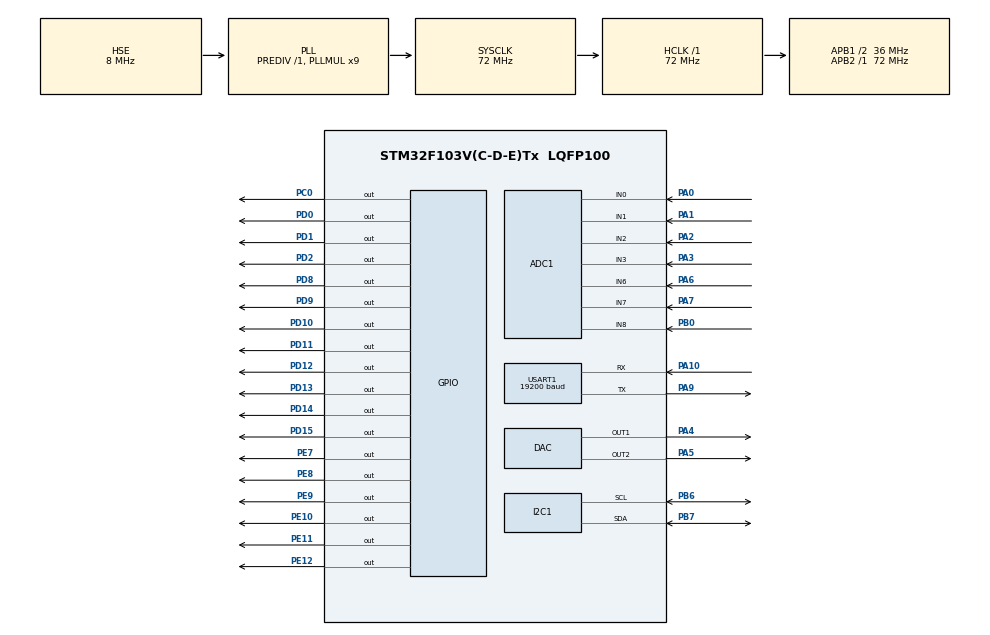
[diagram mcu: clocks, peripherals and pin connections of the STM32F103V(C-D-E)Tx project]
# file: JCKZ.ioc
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ADC1.Channel-10\#ChannelRegularConversion=ADC_CHANNEL_0
ADC1.ContinuousConvMode=DISABLE
ADC1.DataAlign=ADC_DATAALIGN_RIGHT
ADC1.DiscontinuousConvMode=DISABLE
ADC1.EnableAnalogWatchDog=false
ADC1.EnableRegularConversion=ENABLE
ADC1.ExternalTrigConv=ADC_SOFTWARE_START
ADC1.InjNumberOfConversion=0
ADC1.NbrOfConversion=1
ADC1.NbrOfConversionFlag=1
ADC1.Rank-10\#ChannelRegularConversion=1
ADC1.SamplingTime-10\#ChannelRegularConversion=ADC_SAMPLETIME_1CYCLE_5
ADC1.ScanConvMode=ADC_SCAN_DISABLE
ADC1.master=1
FREERTOS.Tasks01=TaskModbusRec,0,128,FuncModbusRec,Default,NULL,Dynamic,NULL,NULL;TaskDataProc,0,128,FuncDataProc,Default,NULL,Dynamic,NULL,NULL;TaskModbusSend,0,128,FuncModbusSend,Default,NULL,Dynamic,NULL,NULL
Mcu.Family=STM32F1
Mcu.Name=STM32F103V(C-D-E)Tx
Mcu.Package=LQFP100
NVIC.ADC1_2_IRQn=true\:5\:0\:false\:false\:true\:true\:true
NVIC.PriorityGroup=NVIC_PRIORITYGROUP_4
NVIC.TIM4_IRQn=true\:0\:0\:false\:false\:true\:false\:false
NVIC.TimeBase=TIM4_IRQn
NVIC.TimeBaseIP=TIM4
NVIC.USART1_IRQn=true\:5\:0\:false\:false\:true\:true\:true
OSC_IN.Mode=HSE-External-Oscillator
OSC_IN.Signal=RCC_OSC_IN
OSC_OUT.Mode=HSE-External-Oscillator
OSC_OUT.Signal=RCC_OSC_OUT
PA0-WKUP.Signal=ADCx_IN0
PA1.Signal=ADCx_IN1
PA10.Mode=Asynchronous
PA10.Signal=USART1_RX
PA2.Signal=ADCx_IN2
PA3.Signal=ADCx_IN3
PA4.Signal=COMP_DAC1_group
PA5.Signal=COMP_DAC2_group
PA6.Signal=ADCx_IN6
PA7.Signal=ADCx_IN7
PA9.Mode=Asynchronous
PA9.Signal=USART1_TX
PB0.Signal=ADCx_IN8
PB6.Mode=I2C
PB6.Signal=I2C1_SCL
PB7.Mode=I2C
PB7.Signal=I2C1_SDA
PC0.Signal=GPIO_Output
PD0.Signal=GPIO_Output
PD1.Signal=GPIO_Output
PD10.Signal=GPIO_Output
PD11.Signal=GPIO_Output
PD12.Signal=GPIO_Output
PD13.Signal=GPIO_Output
PD14.Signal=GPIO_Output
PD15.Signal=GPIO_Output
PD2.Signal=GPIO_Output
PD8.Signal=GPIO_Output
PD9.Signal=GPIO_Output
PE10.Signal=GPIO_Output
PE11.Signal=GPIO_Output
PE12.Signal=GPIO_Output
PE7.Signal=GPIO_Output
PE8.Signal=GPIO_Output
PE9.Signal=GPIO_Output
ProjectManager.HeapSize=0x200
ProjectManager.StackSize=0x400
ProjectManager.TargetToolchain=TrueSTUDIO
RCC.ADCPresc=RCC_ADCPCLK2_DIV6
RCC.AHBFreq_Value=72000000
RCC.APB1CLKDivider=RCC_HCLK_DIV2
RCC.APB1Freq_Value=36000000
RCC.APB1TimFreq_Value=72000000
RCC.APB2Freq_Value=72000000
RCC.APB2TimFreq_Value=72000000
RCC.HCLKFreq_Value=72000000
RCC.PLLMUL=RCC_PLL_MUL9
RCC.PLLSourceVirtual=RCC_PLLSOURCE_HSE
RCC.SYSCLKFreq_VALUE=72000000
RCC.SYSCLKSource=RCC_SYSCLKSOURCE_PLLCLK
RCC.USBFreq_Value=72000000
SH.ADCx_IN0.0=ADC1_IN0,IN0
SH.ADCx_IN1.0=ADC1_IN1,IN1
SH.ADCx_IN2.0=ADC1_IN2,IN2
SH.ADCx_IN3.0=ADC1_IN3,IN3
SH.ADCx_IN6.0=ADC1_IN6,IN6
SH.ADCx_IN7.0=ADC1_IN7,IN7
SH.ADCx_IN8.0=ADC1_IN8,IN8
SH.COMP_DAC1_group.0=DAC_OUT1,DAC_OUT1
SH.COMP_DAC2_group.0=DAC_OUT2,DAC_OUT2
USART1.BaudRate=19200
USART1.VirtualMode=VM_ASYNC
VP_FREERTOS_VS_ENABLE.Mode=Enabled
VP_SYS_VS_ND.Mode=No_Debug
VP_SYS_VS_tim4.Mode=TIM4
board=JCKZ

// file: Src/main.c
/**
  ******************************************************************************
  * File Name          : main.c
  * Description        : Main program body
  ******************************************************************************
  * This notice applies to any and all portions of this file
  * that are not between comment pairs USER CODE BEGIN and
  * USER CODE END. Other portions of this file, whether
  * inserted by the user or by software development tools
  * are owned by their respective copyright owners.
  *
  * Copyright (c) 2017 STMicroelectronics International N.V.
  * All rights reserved.
  *
  * Redistribution and use in source and binary forms, with or without
  * modification, are permitted, provided that the following conditions are met:
  *
  * 1. Redistribution of source code must retain the above copyright notice,
  *    this list of conditions and the following disclaimer.
  * 2. Redistributions in binary form must reproduce the above copyright notice,
  *    this list of conditions and the following disclaimer in the documentation
  *    and/or other materials provided with the distribution.
  * 3. Neither the name of STMicroelectronics nor the names of other
  *    contributors to this software may be used to endorse or promote products
  *    derived from this software without specific written permission.
  * 4. This software, including modifications and/or derivative works of this
  *    software, must execute solely and exclusively on microcontroller or
  *    microprocessor devices manufactured by or for STMicroelectronics.
  * 5. Redistribution and use of this software other than as permitted under
  *    this license is void and will automatically terminate your rights under
  *    this license.
  *
  * THIS SOFTWARE IS PROVIDED BY STMICROELECTRONICS AND CONTRIBUTORS "AS IS"
  * AND ANY EXPRESS, IMPLIED OR STATUTORY WARRANTIES, INCLUDING, BUT NOT
  * LIMITED TO, THE IMPLIED WARRANTIES OF MERCHANTABILITY, FITNESS FOR A
  * PARTICULAR PURPOSE AND NON-INFRINGEMENT OF THIRD PARTY INTELLECTUAL PROPERTY
  * RIGHTS ARE DISCLAIMED TO THE FULLEST EXTENT PERMITTED BY LAW. IN NO EVENT
  * SHALL STMICROELECTRONICS OR CONTRIBUTORS BE LIABLE FOR ANY DIRECT, INDIRECT,
  * INCIDENTAL, SPECIAL, EXEMPLARY, OR CONSEQUENTIAL DAMAGES (INCLUDING, BUT NOT
  * LIMITED TO, PROCUREMENT OF SUBSTITUTE GOODS OR SERVICES; LOSS OF USE, DATA,
  * OR PROFITS; OR BUSINESS INTERRUPTION) HOWEVER CAUSED AND ON ANY THEORY OF
  * LIABILITY, WHETHER IN CONTRACT, STRICT LIABILITY, OR TORT (INCLUDING
  * NEGLIGENCE OR OTHERWISE) ARISING IN ANY WAY OUT OF THE USE OF THIS SOFTWARE,
  * EVEN IF ADVISED OF THE POSSIBILITY OF SUCH DAMAGE.
  *
  ******************************************************************************
  */
#include "main.h"
#include "stm32f1xx_hal.h"
#include "cmsis_os.h"
#include "adc.h"
#include "dac.h"
#include "i2c.h"
#include "usart.h"
#include "gpio.h"

/* USER CODE BEGIN PV */
/* Private variables ---------------------------------------------------------*/

/* USER CODE END PV */

void SystemClock_Config(void);
void MX_FREERTOS_Init(void);

/* USER CODE BEGIN PFP */
/* Private function prototypes -----------------------------------------------*/

/* USER CODE END PFP */

int main(void)
{

  /* MCU Configuration----------------------------------------------------------*/

  /* Reset of all peripherals, Initializes the Flash interface and the Systick. */
  HAL_Init();

  /* Configure the system clock */
  SystemClock_Config();

  /* Initialize all configured peripherals */
  MX_GPIO_Init();
  MX_DAC_Init();
  MX_ADC1_Init();
  MX_USART1_UART_Init();
  MX_I2C1_Init();

  /* USER CODE BEGIN 2 */
  HAL_DAC_Start(&hdac, DAC_CHANNEL_1);
  HAL_DAC_Start(&hdac, DAC_CHANNEL_2);
  /* USER CODE END 2 */

  /* Call init function for freertos objects (in freertos.c) */
  MX_FREERTOS_Init();

  /* Start scheduler */
  osKernelStart();

  /* We should never get here as control is now taken by the scheduler */

  /* Infinite loop */
  while (1)
  {

  }

}

/** System Clock Configuration
*/
void SystemClock_Config(void)
{

  RCC_OscInitTypeDef RCC_OscInitStruct;
  RCC_ClkInitTypeDef RCC_ClkInitStruct;
  RCC_PeriphCLKInitTypeDef PeriphClkInit;

    /**Initializes the CPU, AHB and APB busses clocks
    */
  RCC_OscInitStruct.OscillatorType = RCC_OSCILLATORTYPE_HSE;
  RCC_OscInitStruct.HSEState = RCC_HSE_ON;
  RCC_OscInitStruct.HSEPredivValue = RCC_HSE_PREDIV_DIV1;
  RCC_OscInitStruct.HSIState = RCC_HSI_ON;
  RCC_OscInitStruct.PLL.PLLState = RCC_PLL_ON;
  RCC_OscInitStruct.PLL.PLLSource = RCC_PLLSOURCE_HSE;
  RCC_OscInitStruct.PLL.PLLMUL = RCC_PLL_MUL9;
  if (HAL_RCC_OscConfig(&RCC_OscInitStruct) != HAL_OK)
  {
    _Error_Handler(__FILE__, __LINE__);
  }

    /**Initializes the CPU, AHB and APB busses clocks
    */
  RCC_ClkInitStruct.ClockType = RCC_CLOCKTYPE_HCLK|RCC_CLOCKTYPE_SYSCLK
                              |RCC_CLOCKTYPE_PCLK1|RCC_CLOCKTYPE_PCLK2;
  RCC_ClkInitStruct.SYSCLKSource = RCC_SYSCLKSOURCE_PLLCLK;
  RCC_ClkInitStruct.AHBCLKDivider = RCC_SYSCLK_DIV1;
  RCC_ClkInitStruct.APB1CLKDivider = RCC_HCLK_DIV2;
  RCC_ClkInitStruct.APB2CLKDivider = RCC_HCLK_DIV1;

  if (HAL_RCC_ClockConfig(&RCC_ClkInitStruct, FLASH_LATENCY_2) != HAL_OK)
  {
    _Error_Handler(__FILE__, __LINE__);
  }

  PeriphClkInit.PeriphClockSelection = RCC_PERIPHCLK_ADC;
  PeriphClkInit.AdcClockSelection = RCC_ADCPCLK2_DIV6;
  if (HAL_RCCEx_PeriphCLKConfig(&PeriphClkInit) != HAL_OK)
  {
    _Error_Handler(__FILE__, __LINE__);
  }

    /**Configure the Systick interrupt time
    */
  HAL_SYSTICK_Config(HAL_RCC_GetHCLKFreq()/1000);

    /**Configure the Systick
    */
  HAL_SYSTICK_CLKSourceConfig(SYSTICK_CLKSOURCE_HCLK);

  /* SysTick_IRQn interrupt configuration */
  HAL_NVIC_SetPriority(SysTick_IRQn, 15, 0);
}

void HAL_TIM_PeriodElapsedCallback(TIM_HandleTypeDef *htim)
{
  if (htim->Instance == TIM4) {
    HAL_IncTick();
  }
}

void _Error_Handler(char * file, int line)
{
  while(1)
  {
  }
}

/************************ (C) COPYRIGHT STMicroelectronics *****END OF FILE****/

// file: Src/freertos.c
/**
  ******************************************************************************
  * File Name          : freertos.c
  * Description        : Code for freertos applications
  ******************************************************************************
  * This notice applies to any and all portions of this file
  * that are not between comment pairs USER CODE BEGIN and
  * USER CODE END. Other portions of this file, whether
  * inserted by the user or by software development tools
  * are owned by their respective copyright owners.
  *
  * Copyright (c) 2017 STMicroelectronics International N.V.
  * All rights reserved.
  *
  * Redistribution and use in source and binary forms, with or without
  * modification, are permitted, provided that the following conditions are met:
  *
  * 1. Redistribution of source code must retain the above copyright notice,
  *    this list of conditions and the following disclaimer.
  * 2. Redistributions in binary form must reproduce the above copyright notice,
  *    this list of conditions and the following disclaimer in the documentation
  *    and/or other materials provided with the distribution.
  * 3. Neither the name of STMicroelectronics nor the names of other
  *    contributors to this software may be used to endorse or promote products
  *    derived from this software without specific written permission.
  * 4. This software, including modifications and/or derivative works of this
  *    software, must execute solely and exclusively on microcontroller or
  *    microprocessor devices manufactured by or for STMicroelectronics.
  * 5. Redistribution and use of this software other than as permitted under
  *    this license is void and will automatically terminate your rights under
  *    this license.
  *
  * THIS SOFTWARE IS PROVIDED BY STMICROELECTRONICS AND CONTRIBUTORS "AS IS"
  * AND ANY EXPRESS, IMPLIED OR STATUTORY WARRANTIES, INCLUDING, BUT NOT
  * LIMITED TO, THE IMPLIED WARRANTIES OF MERCHANTABILITY, FITNESS FOR A
  * PARTICULAR PURPOSE AND NON-INFRINGEMENT OF THIRD PARTY INTELLECTUAL PROPERTY
  * RIGHTS ARE DISCLAIMED TO THE FULLEST EXTENT PERMITTED BY LAW. IN NO EVENT
  * SHALL STMICROELECTRONICS OR CONTRIBUTORS BE LIABLE FOR ANY DIRECT, INDIRECT,
  * INCIDENTAL, SPECIAL, EXEMPLARY, OR CONSEQUENTIAL DAMAGES (INCLUDING, BUT NOT
  * LIMITED TO, PROCUREMENT OF SUBSTITUTE GOODS OR SERVICES; LOSS OF USE, DATA,
  * OR PROFITS; OR BUSINESS INTERRUPTION) HOWEVER CAUSED AND ON ANY THEORY OF
  * LIABILITY, WHETHER IN CONTRACT, STRICT LIABILITY, OR TORT (INCLUDING
  * NEGLIGENCE OR OTHERWISE) ARISING IN ANY WAY OUT OF THE USE OF THIS SOFTWARE,
  * EVEN IF ADVISED OF THE POSSIBILITY OF SUCH DAMAGE.
  *
  ******************************************************************************
  */

#include "FreeRTOS.h"
#include "task.h"
#include "cmsis_os.h"

/* USER CODE BEGIN Includes */
#include "stm32f1xx_hal.h"
#include "modbusToAndroid.h"
#include "dataProcessing.h"
/* USER CODE END Includes */

osThreadId TaskModbusRecHandle;
osThreadId TaskDataProcHandle;
osThreadId TaskModbusSendHandle;

void FuncModbusRec(void const * argument);
void FuncDataProc(void const * argument);
void FuncModbusSend(void const * argument);

void MX_FREERTOS_Init(void); /* (MISRA C 2004 rule 8.1) */

/* Hook prototypes */

/* Init FreeRTOS */

void MX_FREERTOS_Init(void) {

  /* Create the thread(s) */
  /* definition and creation of TaskModbusRec */
  osThreadDef(TaskModbusRec, FuncModbusRec, osPriorityNormal, 0, 128);
  TaskModbusRecHandle = osThreadCreate(osThread(TaskModbusRec), NULL);

  /* definition and creation of TaskDataProc */
  osThreadDef(TaskDataProc, FuncDataProc, osPriorityNormal, 0, 128);
  TaskDataProcHandle = osThreadCreate(osThread(TaskDataProc), NULL);

  /* definition and creation of TaskModbusSend */
  osThreadDef(TaskModbusSend, FuncModbusSend, osPriorityNormal, 0, 128);
  TaskModbusSendHandle = osThreadCreate(osThread(TaskModbusSend), NULL);

}

/* FuncModbusRec function */
void FuncModbusRec(void const * argument)
{

  /* USER CODE BEGIN FuncModbusRec */
  /* Infinite loop */
  for(;;)
  {
	  UsartRxMonitor();
	 // osDelay(10);
  }
  /* USER CODE END FuncModbusRec */
}

/* FuncDataProc function */
void FuncDataProc(void const * argument)
{
  /* USER CODE BEGIN FuncDataProc */
  /* Infinite loop */
  for(;;)
  {
	  dataProcessing();
	  //osDelay(10);
  }
  /* USER CODE END FuncDataProc */
}

/* FuncModbusSend function */
void FuncModbusSend(void const * argument)
{
  /* USER CODE BEGIN FuncModbusSend */
  /* Infinite loop */
  for(;;)
  {
	  sendDataMaster03();
	  osDelay(100);
	  sendDataMaster16();
	  osDelay(100);
	  HAL_GPIO_TogglePin(GPIOD, GPIO_PIN_2);

  }
  /* USER CODE END FuncModbusSend */
}

/************************ (C) COPYRIGHT STMicroelectronics *****END OF FILE****/
